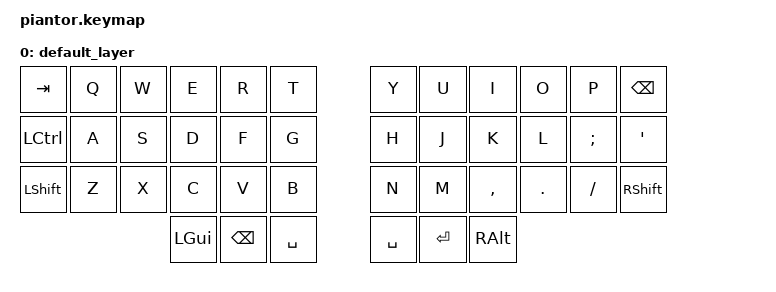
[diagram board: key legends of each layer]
#include <behaviors.dtsi>
#include <dt-bindings/zmk/keys.h>

#include <behaviors.dtsi>
#include <dt-bindings/zmk/keys.h>
#include <dt-bindings/zmk/bt.h>

/ {
    keymap {
        compatible = "zmk,keymap";

        default_layer {
            // -----------------------------------------------------------------------------------------
            // |  TAB |  Q  |  W  |  E  |  R   |  T  |   |  Y  |  U   |  I  |  O  |  P  | BSPC |
            // | CTRL |  A  |  S  |  D  |  F   |  G  |   |  H  |  J   |  K  |  L  |  ;  |  '   |
            // | SHFT |  Z  |  X  |  C  |  V   |  B  |   |  N  |  M   |  ,  |  .  |  /  | SHFT |
            //                    | GUI | BSPC | SPC |   | SPC | ENT  | ALT |
            bindings = <
                &kp TAB   &kp Q &kp W &kp E    &kp R    &kp T        &kp Y     &kp U   &kp I     &kp O   &kp P    &kp BSPC
                &kp LCTRL &kp A &kp S &kp D    &kp F    &kp G        &kp H     &kp J   &kp K     &kp L   &kp SEMI &kp SQT
                &kp LSHFT &kp Z &kp X &kp C    &kp V    &kp B        &kp N     &kp M   &kp COMMA &kp DOT &kp FSLH &kp RSHFT
                                      &kp LGUI &kp BSPC &kp SPACE    &kp SPACE &kp RET &kp RALT
            >;
        };
    };
};
